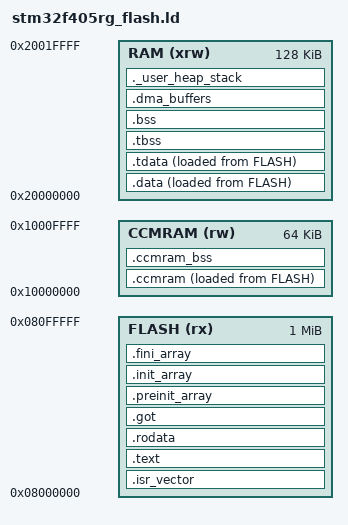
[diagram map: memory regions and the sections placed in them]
/**
 * @file stm32f405rg_flash.ld
 * @brief Main linker script.
 *
 * @details
 * This script controlls code and data placement in flash and ram during linking.
 *
 * @author Aleksander Dziągwa
 * @date 23.08.2026
 */


/* Memories definition */
MEMORY
{
  RAM     (xrw)   : ORIGIN = 0x20000000, LENGTH = 128K
  CCMRAM  (rw)    : ORIGIN = 0x10000000, LENGTH = 64K
  FLASH   (rx)    : ORIGIN = 0x08000000, LENGTH = 1024K
}

/* Entry Point */
ENTRY(Reset_Handler)

/* Highest address of the user mode stack */
_estack = ORIGIN(RAM) + LENGTH(RAM);    /* end of RAM */

_Min_Heap_Size = 0x0;       /* required amount of heap  */
_Min_Stack_Size = 0x400;    /* required amount of stack */

__stack = _estack;
__stack_limit = __stack - _Min_Stack_Size;

/* Define output sections */
SECTIONS
{
  /* The startup code goes first into FLASH */
  .isr_vector :
  {
    . = ALIGN(4);
    KEEP(*(.isr_vector)) /* Startup code */
    . = ALIGN(4);
  } >FLASH


  /* The program code and other data goes into FLASH */
  .text :
  {
    . = ALIGN(4);
    *(.text)           /* .text sections (code) */
    *(.text*)          /* .text* sections (code) */

    KEEP (*(.init))
    KEEP (*(.fini))

    . = ALIGN(4);
    _etext = .;        /* define a global symbols at end of code */
  } >FLASH


  /* Constant data goes into FLASH */
  .rodata :
  {
    . = ALIGN(4);
    *(.rodata)         /* .rodata sections (constants, strings, etc.) */
    *(.rodata*)        /* .rodata* sections (constants, strings, etc.) */
    . = ALIGN(4);
  } >FLASH


  /* Global Offset Table generated by Clang/LLVM */
  .got :
  {
    . = ALIGN(4);
    *(.got .got.*)
    . = ALIGN(4);
  } >FLASH


  .preinit_array :
  {
    . = ALIGN(4);
    PROVIDE_HIDDEN (__preinit_array_start = .);
    KEEP (*(.preinit_array*))
    PROVIDE_HIDDEN (__preinit_array_end = .);
    . = ALIGN(4);
  } >FLASH


  .init_array :
  {
    . = ALIGN(4);
    PROVIDE_HIDDEN (__init_array_start = .);
    KEEP (*(SORT(.init_array.*)))
    KEEP (*(.init_array*))
    PROVIDE_HIDDEN (__init_array_end = .);
    . = ALIGN(4);
  } >FLASH


  .fini_array :
  {
    . = ALIGN(4);
    PROVIDE_HIDDEN (__fini_array_start = .);
    KEEP (*(SORT(.fini_array.*)))
    KEEP (*(.fini_array*))
    PROVIDE_HIDDEN (__fini_array_end = .);
    . = ALIGN(4);
  } >FLASH


  /* CCMRAM data section */
  __ccmram_source = LOADADDR(.ccmram);
  .ccmram :
  {
    . = ALIGN(4);
    __ccmram_start = .;       /* create a global symbol at ccmram start */
    *(.ccmram)
    *(.ccmram*)

    . = ALIGN(4);
    __ccmram_end = .;       /* create a global symbol at ccmram end */
  } >CCMRAM AT> FLASH


  /* Uninitialized CCM-RAM section */
  .ccmram_bss (NOLOAD) :
  {
    . = ALIGN(4);
    __ccmram_bss_start = .;       /* create a global symbol at ccmram_bss start */
    *(.ccmram_bss)
    *(.ccmram_bss*)

    . = ALIGN(4);
    __ccmram_bss_end = .;       /* create a global symbol at ccmram_bss end */
  } >CCMRAM


  /* used by the startup to initialize data */
  __data_source = LOADADDR(.data);


  /* Initialized data section */
  .data :
  {
    . = ALIGN(4);
    __data_start = .;     /* create a global symbol at data start */
    *(.data)              /* .data sections */
    *(.data*)             /* .data* sections */
    . = ALIGN(4);
    __data_end = .;       /* create a global symbol at data end */
    __data_size = . - __data_start;        
  } >RAM AT> FLASH


  /* Thread Local Storage (TLS) initialized data */
  __tdata_source = LOADADDR(.tdata);
  .tdata : ALIGN(8)
  {
    __tls_base = .;
    *(.tdata .tdata.* .gnu.linkonce.td.*)
    . = ALIGN(8);
  } >RAM AT> FLASH


  /* Thread Local Storage (TLS) uninitialized data. */
  .tbss (NOLOAD) : ALIGN(8)
  {
    __tdata_end = .;
    *(.tbss .tbss.* .gnu.linkonce.tb.*)
    *(.tcommon)
    . = ALIGN(8);
    __tls_end = .;
  } >RAM


  .bss (NOLOAD) : ALIGN(4)
  {
    __bss_start = .;         /* define a global symbol at bss start */
    *(.bss)
    *(.bss*)
    *(COMMON)
    . = ALIGN(4);
    __bss_end = .;         /* define a global symbol at bss end */
    PROVIDE( __bss_end = . );
  } >RAM
  PROVIDE( __bss_size = __bss_end - __bss_start );
  PROVIDE( __non_tls_bss_start = ADDR(.bss) );


  /* Required by Picolibc TLS and FreeRTOS static task allocation */
  PROVIDE(__tls_start = SIZEOF(.tdata) ? ADDR(.tdata) : ADDR(.tbss));
  PROVIDE(__tls_size = __tls_end - __tls_start);
  PROVIDE(__tdata_size = SIZEOF(.tdata));
  PROVIDE(__tbss_offset = ADDR(.tbss) - __tls_start);
  PROVIDE(__tbss_size = SIZEOF(.tbss));
  PROVIDE(__tls_align = MAX(ALIGNOF(.tdata), ALIGNOF(.tbss)));
  PROVIDE(__arm32_tls_tcb_offset = MAX(8, __tls_align));


  /* DMA buffers */
  .dma_buffers (NOLOAD) : ALIGN(4)
  {
    . = ALIGN(4);
    KEEP(*(.dma_buffers))
    KEEP(*(.dma_buffers*))
    . = ALIGN(4);
  } >RAM


  /* User_heap_stack section, used to check that there is enough RAM left */
  ._user_heap_stack (NOLOAD) :
  {
    . = ALIGN(8);
    __heap_start = .;
    . = . + _Min_Heap_Size;
    __heap_end = .;
    PROVIDE ( end = . );
    PROVIDE ( _end = . );
    . = . + _Min_Stack_Size;
    . = ALIGN(8);
  } >RAM


  /* Remove information from the standard libraries */
  /DISCARD/ :
  {
    *(.glue_7)         /* Discard ARM to Thumb interworking code */
    *(.glue_7t)        /* Discard Thumb to ARM interworking code */
    *(.eh_frame)       /* Discard generic DWARF exception frames */
    *(.eh_frame_hdr)   
    *(.ARM.extab* .gnu.linkonce.armextab.*) /* Discard C++ exception unwinding */
    *(.ARM.exidx* .gnu.linkonce.armexidx.*)
  }

  .ARM.attributes 0 : { *(.ARM.attributes) }

}

/* Vector table alignement check */
ASSERT((ADDR(.isr_vector) % 512) == 0, "Vector table is not properly aligned");

/* DMA section alignement check */
ASSERT((ADDR(.dma_buffers) % 4) == 0, "DMA section is not properly aligned");

/* Heap and stack collision check */
ASSERT((_end + _Min_Heap_Size + _Min_Stack_Size) <= __stack, "Heap and stack colision");
